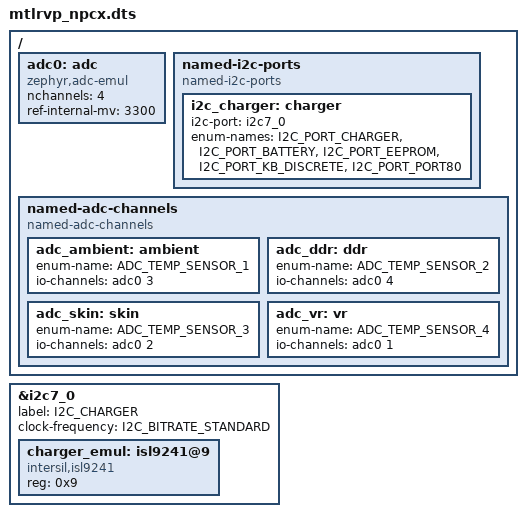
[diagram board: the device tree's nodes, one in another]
/* Copyright 2022 The ChromiumOS Authors
 * Use of this source code is governed by a BSD-style license that can be
 * found in the LICENSE file.
 */

 #include <dt-bindings/usb_pd_tcpm.h>
/ {

	adc0: adc {
		compatible = "zephyr,adc-emul";
		nchannels = <4>;
		ref-internal-mv = <3300>;
		#io-channel-cells = <1>;
		status = "okay";
	};

	named-i2c-ports {
		compatible = "named-i2c-ports";

		i2c_charger: charger {
			i2c-port = <&i2c7_0>;
			enum-names = "I2C_PORT_CHARGER",
				"I2C_PORT_BATTERY",
				"I2C_PORT_EEPROM",
				"I2C_PORT_KB_DISCRETE",
				"I2C_PORT_PORT80";
		};
	};

	named-adc-channels {
		compatible = "named-adc-channels";

		adc_ambient: ambient {
			enum-name = "ADC_TEMP_SENSOR_1";
			io-channels = <&adc0 3>;
		};
		adc_ddr: ddr {
			enum-name = "ADC_TEMP_SENSOR_2";
			io-channels = <&adc0 4>;
		};
		adc_skin: skin {
			enum-name = "ADC_TEMP_SENSOR_3";
			io-channels = <&adc0 2>;
		};
		adc_vr: vr {
			enum-name = "ADC_TEMP_SENSOR_4";
			io-channels = <&adc0 1>;
		};
	};

	
};

/* charger */
&i2c7_0 {
	label = "I2C_CHARGER";
	status = "okay";
	clock-frequency = <I2C_BITRATE_STANDARD>;

	charger_emul: isl9241@9 {
		compatible = "intersil,isl9241";
		status = "okay";
		reg = <0x9>;
	};	
};
